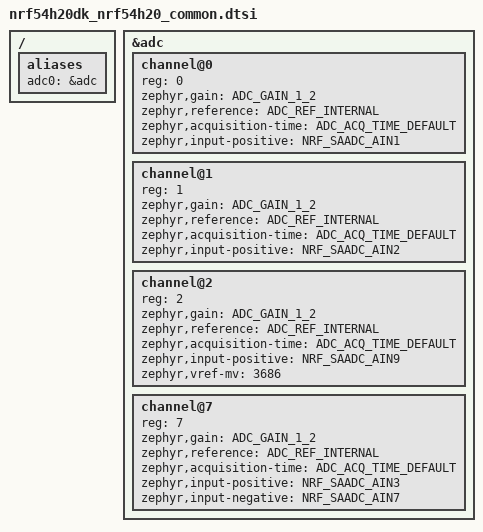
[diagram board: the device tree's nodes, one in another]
/*
 * SPDX-License-Identifier: Apache-2.0
 *
 * Copyright (c) 2025 Nordic Semiconductor ASA
 */

/ {
	aliases {
		adc0 = &adc;
	};
};

&adc {
	#address-cells = <1>;
	#size-cells = <0>;

	channel@0 {
		reg = <0>;
		zephyr,gain = "ADC_GAIN_1_2";
		zephyr,reference = "ADC_REF_INTERNAL";
		zephyr,acquisition-time = <ADC_ACQ_TIME_DEFAULT>;
		zephyr,input-positive = <NRF_SAADC_AIN1>; /* P1.01 */
	};

	channel@1 {
		reg = <1>;
		zephyr,gain = "ADC_GAIN_1_2";
		zephyr,reference = "ADC_REF_INTERNAL";
		zephyr,acquisition-time = <ADC_ACQ_TIME_DEFAULT>;
		zephyr,input-positive = <NRF_SAADC_AIN2>; /* P1.02 */
	};

	channel@2 {
		reg = <2>;
		zephyr,gain = "ADC_GAIN_1_2";
		zephyr,reference = "ADC_REF_INTERNAL";
		zephyr,acquisition-time = <ADC_ACQ_TIME_DEFAULT>;
		zephyr,input-positive = <NRF_SAADC_AIN9>; /* P9.01 */
		zephyr,vref-mv = <3686>; /* 3.6V * 1024 */
	};

	channel@7 {
		reg = <7>;
		zephyr,gain = "ADC_GAIN_1_2";
		zephyr,reference = "ADC_REF_INTERNAL";
		zephyr,acquisition-time = <ADC_ACQ_TIME_DEFAULT>;
		zephyr,input-positive = <NRF_SAADC_AIN3>; /* P1.03 */
		zephyr,input-negative = <NRF_SAADC_AIN7>; /* P1.07 */
	};
};
